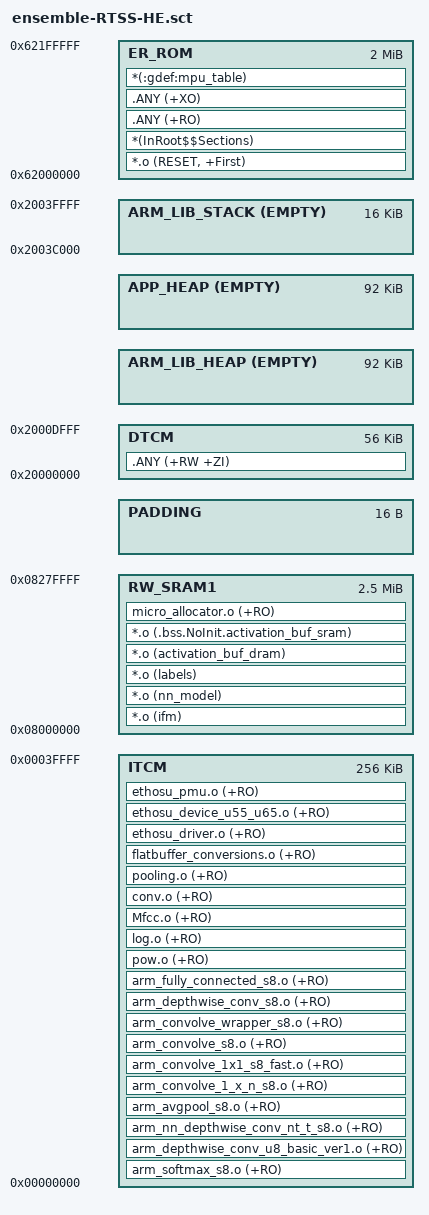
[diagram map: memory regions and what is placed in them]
#! armclang -E --target=arm-arm-none-eabi -mcpu=cortex-m55 -xc
; command above MUST be in first line (no comment above!)

/*On chip RAM Regions */
#define SRAM0_BASE                0x02000000
#define SRAM0_SIZE                0x00400000		/* 4M */
#define SRAM1_BASE                0x08000000
#define SRAM1_SIZE                0x00280000		/* 2.5M */
#define SRAM2_BASE                0x50000000
#define SRAM2_SIZE                0x00040000		/* 256K */
#define SRAM3_BASE                0x50800000
#define SRAM3_SIZE                0x00100000		/* 1M */
#define SRAM4_BASE                0x60000000
#define SRAM4_SIZE                0x00040000		/* 256K */
#define SRAM5_BASE                0x60800000
#define SRAM5_SIZE                0x00040000		/* 256K */
#define SRAM6_BASE                0x62000000
#define SRAM6_SIZE                0x00200000		/* 2M */
#define SRAM7_BASE                0x63000000
#define SRAM7_SIZE                0x00080000		/* 512K */
#define SRAM8_BASE                0x63100000
#define SRAM8_SIZE                0x00200000		/* 2M */
#define SRAM9_BASE                0x64000000
#define SRAM9_SIZE                0x000C0000		/* 768K */
/* On Chip NVM */
#define MRAM_BASE                 0x80000000
#define MRAM_SIZE                 0x00580000		/* 5.5M */

/*--------------------- ITCM Configuration ----------------------------------*/
/* SRAM4 is mapped as ITCM */
#define ITCM_BASE                 0x00000000
#define ITCM_SIZE                 SRAM4_SIZE /* 256K */
#define ITCM_GLOBAL_BASE          SRAM4_BASE

/*--------------------- DTCM Configuration ---------------------------*/
/* SRAM5 is mapped as DTCM */
#define DTCM_BASE                 0x20000000
#define DTCM_SIZE                 SRAM5_SIZE /* 256KB */
#define DTCM_GLOBAL_BASE          SRAM5_BASE

#define __STACK_SIZE    0x00004000
#define __HEAP_SIZE     0x00017000
#define __APP_HEAP_SIZE 0x00017000

;----------------------------------------------------------------------------
;   User Stack & Heap boundary definition
;----------------------------------------------------------------------------
#define __STACK_TOP     (DTCM_BASE + DTCM_SIZE)   /* starts at end of RAM */
#define __HEAP_BASE     (AlignExpr(+0, 8))            /* starts after RW_RAM section, 8 byte aligned */
#define __APP_HEAP_BASE (AlignExpr(+0, 8)) 	          /* starts after HEAP, 8 byte aligned */

;----------------------------------------------------------------------------
;  Scatter File Definitions definition
;----------------------------------------------------------------------------
#define __RO_BASE       SRAM6_BASE
#define __RO_SIZE       SRAM6_SIZE

#define __RW_BASE       DTCM_BASE
#define __RW_SIZE      (DTCM_SIZE - __STACK_SIZE - __HEAP_SIZE - __APP_HEAP_SIZE)


LR_ROM __RO_BASE __RO_SIZE  {                       ; load region size_region
  ER_ROM __RO_BASE __RO_SIZE  {                     ; load address = execution address
   *.o (RESET, +First)
   *(InRoot$$Sections)
   .ANY (+RO)
   .ANY (+XO)
   *(:gdef:mpu_table)
  }

  ITCM ITCM_BASE ITCM_SIZE {  ; --------------------------------
      arm_softmax_s8.o (+RO)
      arm_depthwise_conv_u8_basic_ver1.o (+RO)
      arm_nn_depthwise_conv_nt_t_s8.o (+RO)
      arm_avgpool_s8.o (+RO)
      arm_convolve_1_x_n_s8.o (+RO)
      arm_convolve_1x1_s8_fast.o (+RO)
      arm_convolve_s8.o (+RO)
      arm_convolve_wrapper_s8.o (+RO)
      arm_depthwise_conv_s8.o (+RO)
      arm_fully_connected_s8.o (+RO)

      pow.o (+RO)
      log.o (+RO)
      ;logf.o (+RO)
      Mfcc.o (+RO)
      conv.o (+RO)
      pooling.o (+RO)

      ; Flatbuffer conversion related code
      flatbuffer_conversions.o (+RO)
      ethosu_driver.o (+RO)
      ethosu_device_u55_u65.o (+RO)
      ethosu_pmu.o (+RO)
  }

  ;-----------------------------------------------------
  ; R/W region - ramaining part of the 1MiB RAM region
  ; Other parts of this region used up by stack + heap.
  ;-----------------------------------------------------
  DTCM __RW_BASE __RW_SIZE  {  ; RW data in DTCM
      .ANY (+RW +ZI)
  }

  ARM_LIB_HEAP  __HEAP_BASE EMPTY  __HEAP_SIZE  {  }
  APP_HEAP  __APP_HEAP_BASE EMPTY  __APP_HEAP_SIZE {  }
  ARM_LIB_STACK __STACK_TOP EMPTY -__STACK_SIZE {  }

  RW_SRAM1 SRAM1_BASE ALIGN 16 SRAM1_SIZE  {  ; 2.5MB ----------------------------
      ; nn models baked in input matrices
      *.o (ifm)

      ; nn models default space
      *.o (nn_model)

      ; labels
      *.o (labels)

      ; activation buffers a.k.a tensor arena when memory mode dedicated sram
      *.o (activation_buf_dram)

      ; activation buffers a.k.a tensor arena
      *.o (.bss.NoInit.activation_buf_sram)

      ; micro allocator related code
      micro_allocator.o (+RO)
    }

  PADDING +0 ALIGN 16 FILL 0 16  {  }
}

#if 0
#define _PARTITION_ADDRESS          0x8057F000
#define _PARTITION_SIZE             0x1000

LR_PARTITION _PARTITION_ADDRESS  _PARTITION_SIZE
{
	RESERVED +0 FILL 0 (_PARTITION_SIZE - 16) {}
	ATOC +0 16 { *(:gdef:__mram_atoc) }
}
#endif
